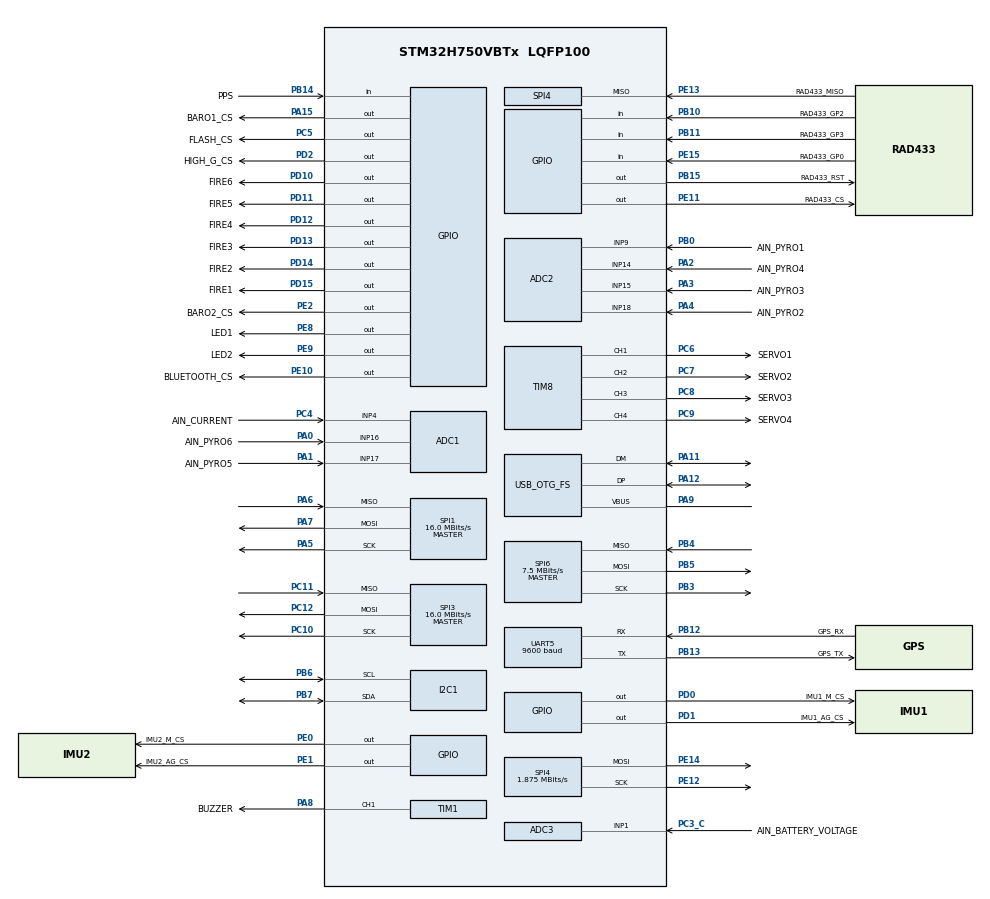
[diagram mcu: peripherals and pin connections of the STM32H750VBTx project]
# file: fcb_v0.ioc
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ADC1.Channel-0\#ChannelRegularConversion=ADC_CHANNEL_4
ADC1.Channel-1\#ChannelRegularConversion=ADC_CHANNEL_16
ADC1.Channel-2\#ChannelRegularConversion=ADC_CHANNEL_17
ADC1.ConversionDataManagement=ADC_CONVERSIONDATA_DMA_ONESHOT
ADC1.NbrOfConversion=3
ADC1.NbrOfConversionFlag=1
ADC1.OffsetNumber-0\#ChannelRegularConversion=ADC_OFFSET_NONE
ADC1.OffsetNumber-1\#ChannelRegularConversion=ADC_OFFSET_NONE
ADC1.OffsetNumber-2\#ChannelRegularConversion=ADC_OFFSET_NONE
ADC1.Rank-0\#ChannelRegularConversion=1
ADC1.Rank-1\#ChannelRegularConversion=2
ADC1.Rank-2\#ChannelRegularConversion=3
ADC1.SamplingTime-0\#ChannelRegularConversion=ADC_SAMPLETIME_1CYCLE_5
ADC1.SamplingTime-1\#ChannelRegularConversion=ADC_SAMPLETIME_1CYCLE_5
ADC1.SamplingTime-2\#ChannelRegularConversion=ADC_SAMPLETIME_1CYCLE_5
ADC1.master=1
ADC2.Channel-0\#ChannelRegularConversion=ADC_CHANNEL_9
ADC2.Channel-1\#ChannelRegularConversion=ADC_CHANNEL_14
ADC2.Channel-2\#ChannelRegularConversion=ADC_CHANNEL_15
ADC2.Channel-3\#ChannelRegularConversion=ADC_CHANNEL_18
ADC2.ConversionDataManagement=ADC_CONVERSIONDATA_DMA_ONESHOT
ADC2.NbrOfConversion=4
ADC2.NbrOfConversionFlag=1
ADC2.OffsetNumber-0\#ChannelRegularConversion=ADC_OFFSET_NONE
ADC2.OffsetNumber-1\#ChannelRegularConversion=ADC_OFFSET_NONE
ADC2.OffsetNumber-2\#ChannelRegularConversion=ADC_OFFSET_NONE
ADC2.OffsetNumber-3\#ChannelRegularConversion=ADC_OFFSET_NONE
ADC2.Rank-0\#ChannelRegularConversion=1
ADC2.Rank-1\#ChannelRegularConversion=2
ADC2.Rank-2\#ChannelRegularConversion=3
ADC2.Rank-3\#ChannelRegularConversion=4
ADC2.SamplingTime-0\#ChannelRegularConversion=ADC_SAMPLETIME_1CYCLE_5
ADC2.SamplingTime-1\#ChannelRegularConversion=ADC_SAMPLETIME_1CYCLE_5
ADC2.SamplingTime-2\#ChannelRegularConversion=ADC_SAMPLETIME_1CYCLE_5
ADC2.SamplingTime-3\#ChannelRegularConversion=ADC_SAMPLETIME_1CYCLE_5
ADC3.Channel-0\#ChannelRegularConversion=ADC_CHANNEL_1
ADC3.ConversionDataManagement=ADC_CONVERSIONDATA_DMA_ONESHOT
ADC3.NbrOfConversionFlag=1
ADC3.OffsetNumber-0\#ChannelRegularConversion=ADC_OFFSET_NONE
ADC3.Rank-0\#ChannelRegularConversion=1
ADC3.SamplingTime-0\#ChannelRegularConversion=ADC_SAMPLETIME_1CYCLE_5
Dma.ADC1.5.Direction=DMA_PERIPH_TO_MEMORY
Dma.ADC1.5.EventEnable=DISABLE
Dma.ADC1.5.FIFOMode=DMA_FIFOMODE_DISABLE
Dma.ADC1.5.Instance=DMA1_Stream5
Dma.ADC1.5.MemDataAlignment=DMA_MDATAALIGN_WORD
Dma.ADC1.5.MemInc=DMA_MINC_ENABLE
Dma.ADC1.5.Mode=DMA_NORMAL
Dma.ADC1.5.PeriphDataAlignment=DMA_PDATAALIGN_WORD
Dma.ADC1.5.PeriphInc=DMA_PINC_DISABLE
Dma.ADC1.5.Polarity=HAL_DMAMUX_REQ_GEN_RISING
Dma.ADC1.5.Priority=DMA_PRIORITY_LOW
Dma.ADC1.5.RequestNumber=1
Dma.ADC1.5.SignalID=NONE
Dma.ADC1.5.SyncEnable=DISABLE
Dma.ADC1.5.SyncPolarity=HAL_DMAMUX_SYNC_NO_EVENT
Dma.ADC1.5.SyncRequestNumber=1
Dma.ADC1.5.SyncSignalID=NONE
Dma.ADC2.6.Direction=DMA_PERIPH_TO_MEMORY
Dma.ADC2.6.EventEnable=DISABLE
Dma.ADC2.6.FIFOMode=DMA_FIFOMODE_DISABLE
Dma.ADC2.6.Instance=DMA1_Stream6
Dma.ADC2.6.MemDataAlignment=DMA_MDATAALIGN_WORD
Dma.ADC2.6.MemInc=DMA_MINC_ENABLE
Dma.ADC2.6.Mode=DMA_NORMAL
Dma.ADC2.6.PeriphDataAlignment=DMA_PDATAALIGN_WORD
Dma.ADC2.6.PeriphInc=DMA_PINC_DISABLE
Dma.ADC2.6.Polarity=HAL_DMAMUX_REQ_GEN_RISING
Dma.ADC2.6.Priority=DMA_PRIORITY_LOW
Dma.ADC2.6.RequestNumber=1
Dma.ADC2.6.SignalID=NONE
Dma.ADC2.6.SyncEnable=DISABLE
Dma.ADC2.6.SyncPolarity=HAL_DMAMUX_SYNC_NO_EVENT
Dma.ADC2.6.SyncRequestNumber=1
Dma.ADC2.6.SyncSignalID=NONE
Dma.ADC3.7.Direction=DMA_PERIPH_TO_MEMORY
Dma.ADC3.7.EventEnable=DISABLE
Dma.ADC3.7.FIFOMode=DMA_FIFOMODE_DISABLE
Dma.ADC3.7.Instance=DMA1_Stream7
Dma.ADC3.7.MemDataAlignment=DMA_MDATAALIGN_WORD
Dma.ADC3.7.MemInc=DMA_MINC_ENABLE
Dma.ADC3.7.Mode=DMA_NORMAL
Dma.ADC3.7.PeriphDataAlignment=DMA_PDATAALIGN_WORD
Dma.ADC3.7.PeriphInc=DMA_PINC_DISABLE
Dma.ADC3.7.Polarity=HAL_DMAMUX_REQ_GEN_RISING
Dma.ADC3.7.Priority=DMA_PRIORITY_LOW
Dma.ADC3.7.RequestNumber=1
Dma.ADC3.7.SignalID=NONE
Dma.ADC3.7.SyncEnable=DISABLE
Dma.ADC3.7.SyncPolarity=HAL_DMAMUX_SYNC_NO_EVENT
Dma.ADC3.7.SyncRequestNumber=1
Dma.ADC3.7.SyncSignalID=NONE
Dma.Request0=UART5_RX
Dma.Request1=SPI1_TX
Dma.Request2=SPI1_RX
Dma.Request3=SPI3_TX
Dma.Request4=SPI3_RX
Dma.Request5=ADC1
Dma.Request6=ADC2
Dma.Request7=ADC3
Dma.SPI1_RX.2.Direction=DMA_PERIPH_TO_MEMORY
Dma.SPI1_RX.2.EventEnable=DISABLE
Dma.SPI1_RX.2.FIFOMode=DMA_FIFOMODE_DISABLE
Dma.SPI1_RX.2.Instance=DMA1_Stream2
Dma.SPI1_RX.2.MemDataAlignment=DMA_MDATAALIGN_BYTE
Dma.SPI1_RX.2.MemInc=DMA_MINC_ENABLE
Dma.SPI1_RX.2.Mode=DMA_NORMAL
Dma.SPI1_RX.2.PeriphDataAlignment=DMA_PDATAALIGN_BYTE
Dma.SPI1_RX.2.PeriphInc=DMA_PINC_DISABLE
Dma.SPI1_RX.2.Polarity=HAL_DMAMUX_REQ_GEN_RISING
Dma.SPI1_RX.2.Priority=DMA_PRIORITY_LOW
Dma.SPI1_RX.2.RequestNumber=1
Dma.SPI1_RX.2.SignalID=NONE
Dma.SPI1_RX.2.SyncEnable=DISABLE
Dma.SPI1_RX.2.SyncPolarity=HAL_DMAMUX_SYNC_NO_EVENT
Dma.SPI1_RX.2.SyncRequestNumber=1
Dma.SPI1_RX.2.SyncSignalID=NONE
Dma.SPI1_TX.1.Direction=DMA_MEMORY_TO_PERIPH
Dma.SPI1_TX.1.EventEnable=DISABLE
Dma.SPI1_TX.1.FIFOMode=DMA_FIFOMODE_DISABLE
Dma.SPI1_TX.1.Instance=DMA1_Stream1
Dma.SPI1_TX.1.MemDataAlignment=DMA_MDATAALIGN_BYTE
Dma.SPI1_TX.1.MemInc=DMA_MINC_ENABLE
Dma.SPI1_TX.1.Mode=DMA_NORMAL
Dma.SPI1_TX.1.PeriphDataAlignment=DMA_PDATAALIGN_BYTE
Dma.SPI1_TX.1.PeriphInc=DMA_PINC_DISABLE
Dma.SPI1_TX.1.Polarity=HAL_DMAMUX_REQ_GEN_RISING
Dma.SPI1_TX.1.Priority=DMA_PRIORITY_LOW
Dma.SPI1_TX.1.RequestNumber=1
Dma.SPI1_TX.1.SignalID=NONE
Dma.SPI1_TX.1.SyncEnable=DISABLE
Dma.SPI1_TX.1.SyncPolarity=HAL_DMAMUX_SYNC_NO_EVENT
Dma.SPI1_TX.1.SyncRequestNumber=1
Dma.SPI1_TX.1.SyncSignalID=NONE
Dma.SPI3_RX.4.Direction=DMA_PERIPH_TO_MEMORY
Dma.SPI3_RX.4.EventEnable=DISABLE
Dma.SPI3_RX.4.FIFOMode=DMA_FIFOMODE_DISABLE
Dma.SPI3_RX.4.Instance=DMA1_Stream4
Dma.SPI3_RX.4.MemDataAlignment=DMA_MDATAALIGN_BYTE
Dma.SPI3_RX.4.MemInc=DMA_MINC_ENABLE
Dma.SPI3_RX.4.Mode=DMA_NORMAL
Dma.SPI3_RX.4.PeriphDataAlignment=DMA_PDATAALIGN_BYTE
Dma.SPI3_RX.4.PeriphInc=DMA_PINC_DISABLE
Dma.SPI3_RX.4.Polarity=HAL_DMAMUX_REQ_GEN_RISING
Dma.SPI3_RX.4.Priority=DMA_PRIORITY_LOW
Dma.SPI3_RX.4.RequestNumber=1
Dma.SPI3_RX.4.SignalID=NONE
Dma.SPI3_RX.4.SyncEnable=DISABLE
Dma.SPI3_RX.4.SyncPolarity=HAL_DMAMUX_SYNC_NO_EVENT
Dma.SPI3_RX.4.SyncRequestNumber=1
Dma.SPI3_RX.4.SyncSignalID=NONE
Dma.SPI3_TX.3.Direction=DMA_MEMORY_TO_PERIPH
Dma.SPI3_TX.3.EventEnable=DISABLE
Dma.SPI3_TX.3.FIFOMode=DMA_FIFOMODE_DISABLE
Dma.SPI3_TX.3.Instance=DMA1_Stream3
Dma.SPI3_TX.3.MemDataAlignment=DMA_MDATAALIGN_BYTE
Dma.SPI3_TX.3.MemInc=DMA_MINC_ENABLE
Dma.SPI3_TX.3.Mode=DMA_NORMAL
Dma.SPI3_TX.3.PeriphDataAlignment=DMA_PDATAALIGN_BYTE
Dma.SPI3_TX.3.PeriphInc=DMA_PINC_DISABLE
Dma.SPI3_TX.3.Polarity=HAL_DMAMUX_REQ_GEN_RISING
Dma.SPI3_TX.3.Priority=DMA_PRIORITY_LOW
Dma.SPI3_TX.3.RequestNumber=1
Dma.SPI3_TX.3.SignalID=NONE
Dma.SPI3_TX.3.SyncEnable=DISABLE
Dma.SPI3_TX.3.SyncPolarity=HAL_DMAMUX_SYNC_NO_EVENT
Dma.SPI3_TX.3.SyncRequestNumber=1
Dma.SPI3_TX.3.SyncSignalID=NONE
Dma.UART5_RX.0.Direction=DMA_PERIPH_TO_MEMORY
Dma.UART5_RX.0.EventEnable=DISABLE
Dma.UART5_RX.0.FIFOMode=DMA_FIFOMODE_DISABLE
Dma.UART5_RX.0.Instance=DMA1_Stream0
Dma.UART5_RX.0.MemDataAlignment=DMA_MDATAALIGN_BYTE
Dma.UART5_RX.0.MemInc=DMA_MINC_ENABLE
Dma.UART5_RX.0.Mode=DMA_NORMAL
Dma.UART5_RX.0.PeriphDataAlignment=DMA_PDATAALIGN_BYTE
Dma.UART5_RX.0.PeriphInc=DMA_PINC_DISABLE
Dma.UART5_RX.0.Polarity=HAL_DMAMUX_REQ_GEN_RISING
Dma.UART5_RX.0.Priority=DMA_PRIORITY_HIGH
Dma.UART5_RX.0.RequestNumber=1
Dma.UART5_RX.0.SignalID=NONE
Dma.UART5_RX.0.SyncEnable=DISABLE
Dma.UART5_RX.0.SyncPolarity=HAL_DMAMUX_SYNC_NO_EVENT
Dma.UART5_RX.0.SyncRequestNumber=1
Dma.UART5_RX.0.SyncSignalID=NONE
I2C1.Timing=0x307075B1
IWDG1.Prescaler=IWDG_PRESCALER_128
IWDG1.Reload=1249
Mcu.Family=STM32H7
Mcu.Name=STM32H750VBTx
Mcu.Package=LQFP100
NVIC.DMA1_Stream0_IRQn=true\:0\:0\:false\:false\:true\:false\:true\:true
NVIC.DMA1_Stream1_IRQn=true\:0\:0\:false\:false\:true\:false\:true\:true
NVIC.DMA1_Stream2_IRQn=true\:0\:0\:false\:false\:true\:false\:true\:true
NVIC.DMA1_Stream3_IRQn=true\:0\:0\:false\:false\:true\:false\:true\:true
NVIC.DMA1_Stream4_IRQn=true\:0\:0\:false\:false\:true\:false\:true\:true
NVIC.DMA1_Stream5_IRQn=true\:0\:0\:false\:false\:true\:false\:true\:true
NVIC.DMA1_Stream6_IRQn=true\:0\:0\:false\:false\:true\:false\:true\:true
NVIC.DMA1_Stream7_IRQn=true\:0\:0\:false\:false\:true\:false\:true\:true
NVIC.OTG_FS_IRQn=true\:0\:0\:false\:false\:true\:true\:true\:true
NVIC.PriorityGroup=NVIC_PRIORITYGROUP_4
NVIC.SPI1_IRQn=true\:0\:0\:false\:false\:true\:false\:true\:true
NVIC.SPI3_IRQn=true\:0\:0\:false\:false\:true\:false\:true\:true
NVIC.TIM2_IRQn=true\:0\:0\:false\:false\:true\:true\:true\:true
NVIC.UART5_IRQn=true\:0\:0\:false\:false\:true\:true\:true\:true
PA0.GPIO_Label=AIN_PYRO6
PA0.Mode=IN16-Single-Ended
PA0.Signal=ADC1_INP16
PA1.GPIO_Label=AIN_PYRO5
PA1.Mode=IN17-Single-Ended
PA1.Signal=ADC1_INP17
PA11.Mode=Device_Only
PA11.Signal=USB_OTG_FS_DM
PA12.Mode=Device_Only
PA12.Signal=USB_OTG_FS_DP
PA13\ (JTMS/SWDIO).Mode=Serial_Wire
PA13\ (JTMS/SWDIO).Signal=DEBUG_JTMS-SWDIO
PA14\ (JTCK/SWCLK).Mode=Serial_Wire
PA14\ (JTCK/SWCLK).Signal=DEBUG_JTCK-SWCLK
PA15\ (JTDI).GPIO_Label=BARO1_CS
PA15\ (JTDI).PinState=GPIO_PIN_SET
PA15\ (JTDI).Signal=GPIO_Output
PA2.GPIO_Label=AIN_PYRO4
PA2.Signal=ADCx_INP14
PA3.GPIO_Label=AIN_PYRO3
PA3.Signal=ADCx_INP15
PA4.GPIO_Label=AIN_PYRO2
PA4.Signal=ADCx_INP18
PA5.Mode=Full_Duplex_Master
PA5.Signal=SPI1_SCK
PA6.Mode=Full_Duplex_Master
PA6.Signal=SPI1_MISO
PA7.Mode=Full_Duplex_Master
PA7.Signal=SPI1_MOSI
PA8.GPIO_Label=BUZZER
PA8.Signal=S_TIM1_CH1
PA9.Mode=Activate_VBUS
PA9.Signal=USB_OTG_FS_VBUS
PB0.GPIO_Label=AIN_PYRO1
PB0.Signal=ADCx_INP9
PB10.GPIO_Label=RAD433_GP2
PB10.Signal=GPIO_Input
PB11.GPIO_Label=RAD433_GP3
PB11.Signal=GPIO_Input
PB12.GPIO_Label=GPS_RX
PB12.Mode=Asynchronous
PB12.Signal=UART5_RX
PB13.GPIO_Label=GPS_TX
PB13.Mode=Asynchronous
PB13.Signal=UART5_TX
PB14.GPIO_Label=PPS
PB14.Signal=GPIO_Input
PB15.GPIO_Label=RAD433_RST
PB15.Signal=GPIO_Output
PB3\ (JTDO/TRACESWO).Mode=Full_Duplex_Master
PB3\ (JTDO/TRACESWO).Signal=SPI6_SCK
PB4\ (NJTRST).Mode=Full_Duplex_Master
PB4\ (NJTRST).Signal=SPI6_MISO
PB5.Mode=Full_Duplex_Master
PB5.Signal=SPI6_MOSI
PB6.Mode=I2C
PB6.Signal=I2C1_SCL
PB7.Mode=I2C
PB7.Signal=I2C1_SDA
PC10.Mode=Full_Duplex_Master
PC10.Signal=SPI3_SCK
PC11.Mode=Full_Duplex_Master
PC11.Signal=SPI3_MISO
PC12.Mode=Full_Duplex_Master
PC12.Signal=SPI3_MOSI
PC14-OSC32_IN\ (OSC32_IN).Mode=LSE-External-Oscillator
PC14-OSC32_IN\ (OSC32_IN).Signal=RCC_OSC32_IN
PC15-OSC32_OUT\ (OSC32_OUT).Mode=LSE-External-Oscillator
PC15-OSC32_OUT\ (OSC32_OUT).Signal=RCC_OSC32_OUT
PC3_C.GPIO_Label=AIN_BATTERY_VOLTAGE
PC3_C.Mode=IN1-Single-Ended
PC3_C.Signal=ADC3_INP1
PC4.GPIO_Label=AIN_CURRENT
PC4.Signal=ADCx_INP4
PC5.GPIO_Label=FLASH_CS
PC5.PinState=GPIO_PIN_SET
PC5.Signal=GPIO_Output
PC6.GPIO_Label=SERVO1
PC6.Signal=S_TIM8_CH1
PC7.GPIO_Label=SERVO2
PC7.Signal=S_TIM8_CH2
PC8.GPIO_Label=SERVO3
PC8.Signal=S_TIM8_CH3
PC9.GPIO_Label=SERVO4
PC9.Signal=S_TIM8_CH4
PD0.GPIO_Label=IMU1_M_CS
PD0.PinState=GPIO_PIN_SET
PD0.Signal=GPIO_Output
PD1.GPIO_Label=IMU1_AG_CS
PD1.PinState=GPIO_PIN_SET
PD1.Signal=GPIO_Output
PD10.GPIO_Label=FIRE6
PD10.Signal=GPIO_Output
PD11.GPIO_Label=FIRE5
PD11.Signal=GPIO_Output
PD12.GPIO_Label=FIRE4
PD12.Signal=GPIO_Output
PD13.GPIO_Label=FIRE3
PD13.Signal=GPIO_Output
PD14.GPIO_Label=FIRE2
PD14.Signal=GPIO_Output
PD15.GPIO_Label=FIRE1
PD15.Signal=GPIO_Output
PD2.GPIO_Label=HIGH_G_CS
PD2.PinState=GPIO_PIN_SET
PD2.Signal=GPIO_Output
PE0.GPIO_Label=IMU2_M_CS
PE0.PinState=GPIO_PIN_SET
PE0.Signal=GPIO_Output
PE1.GPIO_Label=IMU2_AG_CS
PE1.PinState=GPIO_PIN_SET
PE1.Signal=GPIO_Output
PE10.GPIO_Label=BLUETOOTH_CS
PE10.PinState=GPIO_PIN_SET
PE10.Signal=GPIO_Output
PE11.GPIO_Label=RAD433_CS
PE11.PinState=GPIO_PIN_SET
PE11.Signal=GPIO_Output
PE12.Mode=Full_Duplex_Master
PE12.Signal=SPI4_SCK
PE13.GPIO_Label=RAD433_MISO
PE13.Mode=Full_Duplex_Master
PE13.Signal=SPI4_MISO
PE14.Mode=Full_Duplex_Master
PE14.Signal=SPI4_MOSI
PE15.GPIO_Label=RAD433_GP0
PE15.Signal=GPIO_Input
PE2.GPIO_Label=BARO2_CS
PE2.PinState=GPIO_PIN_SET
PE2.Signal=GPIO_Output
PE8.GPIO_Label=LED1
PE8.Signal=GPIO_Output
PE9.GPIO_Label=LED2
PE9.Signal=GPIO_Output
PH0-OSC_IN\ (PH0).Mode=HSE-External-Oscillator
PH0-OSC_IN\ (PH0).Signal=RCC_OSC_IN
PH1-OSC_OUT\ (PH1).Mode=HSE-External-Oscillator
PH1-OSC_OUT\ (PH1).Signal=RCC_OSC_OUT
ProjectManager.HeapSize=0x200
ProjectManager.StackSize=0x400
ProjectManager.TargetToolchain=STM32CubeIDE
RCC.ADCFreq_Value=75000000
RCC.APB1Freq_Value=120000000
RCC.APB2Freq_Value=120000000
RCC.APB3Freq_Value=120000000
RCC.APB4Freq_Value=120000000
RCC.CKPERSourceSelection=RCC_CLKPSOURCE_HSE
RCC.CortexFreq_Value=480000000
RCC.D1PPRE=RCC_APB3_DIV2
RCC.D2PPRE1=RCC_APB1_DIV2
RCC.D2PPRE2=RCC_APB2_DIV2
RCC.D3PPRE=RCC_APB4_DIV2
RCC.DIVM1=5
RCC.DIVM2=2
RCC.DIVN1=192
RCC.DIVN2=12
RCC.DIVQ1=15
RCC.EnbaleCSS=false
RCC.HCLKFreq_Value=240000000
RCC.HPRE=RCC_HCLK_DIV2
RCC.PLL2FRACN=0
RCC.PLL3FRACN=0
RCC.PLL3_VCI_Range-AdvancedSettings=RCC_PLL3VCIRANGE_2
RCC.PLLFRACN=0
RCC.PLLSourceVirtual=RCC_PLLSOURCE_HSE
RCC.PWR_Regulator_Voltage_Scale=PWR_REGULATOR_VOLTAGE_SCALE0
RCC.RTCClockSelection=RCC_RTCCLKSOURCE_LSE
RCC.SYSCLKFreq_VALUE=480000000
RCC.SYSCLKSource=RCC_SYSCLKSOURCE_PLLCLK
RCC.SupplySource=PWR_LDO_SUPPLY
RCC.USBCLockSelection=RCC_USBCLKSOURCE_HSI48
RCC.USBFreq_Value=48000000
SH.ADCx_INP14.0=ADC2_INP14,IN14-Single-Ended
SH.ADCx_INP15.0=ADC2_INP15,IN15-Single-Ended
SH.ADCx_INP18.0=ADC1_INP18
SH.ADCx_INP18.1=ADC2_INP18,IN18-Single-Ended
SH.ADCx_INP4.0=ADC1_INP4,IN4-Single-Ended
SH.ADCx_INP9.0=ADC2_INP9,IN9-Single-Ended
SH.S_TIM1_CH1.0=TIM1_CH1,PWM Generation1 CH1
SH.S_TIM8_CH1.0=TIM8_CH1,PWM Generation1 CH1
SH.S_TIM8_CH2.0=TIM8_CH2,PWM Generation2 CH2
SH.S_TIM8_CH3.0=TIM8_CH3,PWM Generation3 CH3
SH.S_TIM8_CH4.0=TIM8_CH4,PWM Generation4 CH4
SPI1.BaudRatePrescaler=SPI_BAUDRATEPRESCALER_4
SPI1.CalculateBaudRate=16.0 MBits/s
SPI1.DataSize=SPI_DATASIZE_8BIT
SPI1.Direction=SPI_DIRECTION_2LINES
SPI1.Mode=SPI_MODE_MASTER
SPI1.VirtualType=VM_MASTER
SPI3.BaudRatePrescaler=SPI_BAUDRATEPRESCALER_4
SPI3.CalculateBaudRate=16.0 MBits/s
SPI3.DataSize=SPI_DATASIZE_8BIT
SPI3.Direction=SPI_DIRECTION_2LINES
SPI3.Mode=SPI_MODE_MASTER
SPI3.VirtualType=VM_MASTER
SPI4.BaudRatePrescaler=SPI_BAUDRATEPRESCALER_64
SPI4.CalculateBaudRate=1.875 MBits/s
SPI4.DataSize=SPI_DATASIZE_8BIT
SPI4.Direction=SPI_DIRECTION_2LINES
SPI4.Mode=SPI_MODE_MASTER
SPI4.VirtualType=VM_MASTER
SPI6.BaudRatePrescaler=SPI_BAUDRATEPRESCALER_16
SPI6.CalculateBaudRate=7.5 MBits/s
SPI6.DataSize=SPI_DATASIZE_8BIT
SPI6.Direction=SPI_DIRECTION_2LINES
SPI6.Mode=SPI_MODE_MASTER
SPI6.VirtualType=VM_MASTER
TIM1.AutoReloadPreload=TIM_AUTORELOAD_PRELOAD_ENABLE
TIM1.Channel-PWM\ Generation1\ CH1=TIM_CHANNEL_1
TIM2.AutoReloadPreload=TIM_AUTORELOAD_PRELOAD_ENABLE
TIM2.Period=120000
TIM2.Prescaler=1
TIM8.AutoReloadPreload=TIM_AUTORELOAD_PRELOAD_ENABLE
TIM8.Channel-PWM\ Generation1\ CH1=TIM_CHANNEL_1
TIM8.Channel-PWM\ Generation2\ CH2=TIM_CHANNEL_2
TIM8.Channel-PWM\ Generation3\ CH3=TIM_CHANNEL_3
TIM8.Channel-PWM\ Generation4\ CH4=TIM_CHANNEL_4
UART5.BaudRate=9600
UART5.OverrunDisableParam=UART_ADVFEATURE_OVERRUN_ENABLE
USB_OTG_FS.VirtualMode=Device_Only
VP_IWDG1_VS_IWDG.Mode=IWDG_Activate
VP_RTC_VS_RTC_Activate.Mode=RTC_Enabled
VP_TIM2_VS_ClockSourceINT.Mode=Internal
board=custom

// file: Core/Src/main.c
/* USER CODE BEGIN Header */
/**
 ******************************************************************************
 * @file           : main.c
 * @brief          : Main program body
 ******************************************************************************
 * @attention
 *
 * <h2><center>&copy; Copyright (c) 2023 STMicroelectronics.
 * All rights reserved.</center></h2>
 *
 * This software component is licensed by ST under Ultimate Liberty license
 * SLA0044, the "License"; You may not use this file except in compliance with
 * the License. You may obtain a copy of the License at:
 *                             www.st.com/SLA0044
 *
 ******************************************************************************
 */
/* USER CODE END Header */
#include "main.h"

#include "adc.h"
#include "dma.h"
#include "gpio.h"
#include "i2c.h"
#include "iwdg.h"
#include "rtc.h"
#include "spi.h"
#include "tim.h"
#include "usart.h"
#include "usb_device.h"

/* USER CODE BEGIN Includes */
#include "entrypoint.h"
/* USER CODE END Includes */

void SystemClock_Config(void);
void PeriphCommonClock_Config(void);

int main(void) {

  /* MCU Configuration--------------------------------------------------------*/

  /* Reset of all peripherals, Initializes the Flash interface and the Systick.
   */
  HAL_Init();

  /* Configure the system clock */
  SystemClock_Config();

  /* Configure the peripherals common clocks */
  PeriphCommonClock_Config();

  /* Initialize all configured peripherals */
  MX_GPIO_Init();
  MX_DMA_Init();
  MX_ADC1_Init();
  MX_ADC2_Init();
  MX_ADC3_Init();
  MX_I2C1_Init();
  MX_RTC_Init();
  MX_SPI1_Init();
  MX_SPI3_Init();
  MX_SPI4_Init();
  MX_SPI6_Init();
  MX_TIM1_Init();
  MX_TIM8_Init();
  MX_UART5_Init();
  MX_USB_DEVICE_Init();
  MX_IWDG1_Init();
  MX_TIM2_Init();
  /* USER CODE BEGIN 2 */

  main_cpp();

  /* USER CODE END 2 */

  /* Infinite loop */
  while (1) {

  }
}

void SystemClock_Config(void) {
  RCC_OscInitTypeDef RCC_OscInitStruct = {0};
  RCC_ClkInitTypeDef RCC_ClkInitStruct = {0};

  /** Supply configuration update enable
   */
  HAL_PWREx_ConfigSupply(PWR_LDO_SUPPLY);
  /** Configure the main internal regulator output voltage
   */
  __HAL_PWR_VOLTAGESCALING_CONFIG(PWR_REGULATOR_VOLTAGE_SCALE0);

  while (!__HAL_PWR_GET_FLAG(PWR_FLAG_VOSRDY)) {
  }
  /** Configure LSE Drive Capability
   */
  HAL_PWR_EnableBkUpAccess();
  __HAL_RCC_LSEDRIVE_CONFIG(RCC_LSEDRIVE_LOW);
  /** Macro to configure the PLL clock source
   */
  __HAL_RCC_PLL_PLLSOURCE_CONFIG(RCC_PLLSOURCE_HSE);
  /** Initializes the RCC Oscillators according to the specified parameters
   * in the RCC_OscInitTypeDef structure.
   */
  RCC_OscInitStruct.OscillatorType =
      RCC_OSCILLATORTYPE_HSI48 | RCC_OSCILLATORTYPE_LSI |
      RCC_OSCILLATORTYPE_HSE | RCC_OSCILLATORTYPE_LSE;
  RCC_OscInitStruct.HSEState = RCC_HSE_ON;
  RCC_OscInitStruct.LSEState = RCC_LSE_ON;
  RCC_OscInitStruct.LSIState = RCC_LSI_ON;
  RCC_OscInitStruct.HSI48State = RCC_HSI48_ON;
  RCC_OscInitStruct.PLL.PLLState = RCC_PLL_ON;
  RCC_OscInitStruct.PLL.PLLSource = RCC_PLLSOURCE_HSE;
  RCC_OscInitStruct.PLL.PLLM = 5;
  RCC_OscInitStruct.PLL.PLLN = 192;
  RCC_OscInitStruct.PLL.PLLP = 2;
  RCC_OscInitStruct.PLL.PLLQ = 15;
  RCC_OscInitStruct.PLL.PLLR = 2;
  RCC_OscInitStruct.PLL.PLLRGE = RCC_PLL1VCIRANGE_2;
  RCC_OscInitStruct.PLL.PLLVCOSEL = RCC_PLL1VCOWIDE;
  RCC_OscInitStruct.PLL.PLLFRACN = 0;
  if (HAL_RCC_OscConfig(&RCC_OscInitStruct) != HAL_OK) {
    Error_Handler();
  }
  /** Initializes the CPU, AHB and APB buses clocks
   */
  RCC_ClkInitStruct.ClockType = RCC_CLOCKTYPE_HCLK | RCC_CLOCKTYPE_SYSCLK |
                                RCC_CLOCKTYPE_PCLK1 | RCC_CLOCKTYPE_PCLK2 |
                                RCC_CLOCKTYPE_D3PCLK1 | RCC_CLOCKTYPE_D1PCLK1;
  RCC_ClkInitStruct.SYSCLKSource = RCC_SYSCLKSOURCE_PLLCLK;
  RCC_ClkInitStruct.SYSCLKDivider = RCC_SYSCLK_DIV1;
  RCC_ClkInitStruct.AHBCLKDivider = RCC_HCLK_DIV2;
  RCC_ClkInitStruct.APB3CLKDivider = RCC_APB3_DIV2;
  RCC_ClkInitStruct.APB1CLKDivider = RCC_APB1_DIV2;
  RCC_ClkInitStruct.APB2CLKDivider = RCC_APB2_DIV2;
  RCC_ClkInitStruct.APB4CLKDivider = RCC_APB4_DIV2;

  if (HAL_RCC_ClockConfig(&RCC_ClkInitStruct, FLASH_LATENCY_4) != HAL_OK) {
    Error_Handler();
  }
}

void PeriphCommonClock_Config(void) {
  RCC_PeriphCLKInitTypeDef PeriphClkInitStruct = {0};

  /** Initializes the peripherals clock
   */
  PeriphClkInitStruct.PeriphClockSelection = RCC_PERIPHCLK_ADC;
  PeriphClkInitStruct.PLL2.PLL2M = 2;
  PeriphClkInitStruct.PLL2.PLL2N = 12;
  PeriphClkInitStruct.PLL2.PLL2P = 2;
  PeriphClkInitStruct.PLL2.PLL2Q = 2;
  PeriphClkInitStruct.PLL2.PLL2R = 2;
  PeriphClkInitStruct.PLL2.PLL2RGE = RCC_PLL2VCIRANGE_3;
  PeriphClkInitStruct.PLL2.PLL2VCOSEL = RCC_PLL2VCOMEDIUM;
  PeriphClkInitStruct.PLL2.PLL2FRACN = 0;
  PeriphClkInitStruct.AdcClockSelection = RCC_ADCCLKSOURCE_PLL2;
  if (HAL_RCCEx_PeriphCLKConfig(&PeriphClkInitStruct) != HAL_OK) {
    Error_Handler();
  }
}

void Error_Handler(void) {
  __disable_irq();
  while (1) {
  }
}

#ifdef USE_FULL_ASSERT
/**
 * @brief  Reports the name of the source file and the source line number
 *         where the assert_param error has occurred.
 * @param  file: pointer to the source file name
 * @param  line: assert_param error line source number
 * @retval None
 */
void assert_failed(uint8_t *file, uint32_t line) {
  /* USER CODE BEGIN 6 */
  /* User can add his own implementation to report the file name and line
     number, ex: printf("Wrong parameters value: file %s on line %d\r\n", file,
     line) */
  /* USER CODE END 6 */
}
#endif /* USE_FULL_ASSERT */

/************************ (C) COPYRIGHT STMicroelectronics *****END OF FILE****/
